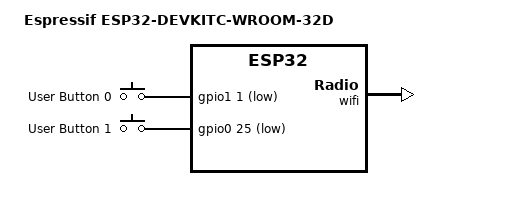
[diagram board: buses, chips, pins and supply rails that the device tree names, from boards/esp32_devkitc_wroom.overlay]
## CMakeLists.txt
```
# SPDX-License-Identifier: Apache-2.0

cmake_minimum_required(VERSION 3.20.0)

find_package(Zephyr REQUIRED HINTS $ENV{ZEPHYR_BASE})
project(mqtt_publisher)

FILE(GLOB app_sources src/*.c)
target_sources(app PRIVATE ${app_sources})
target_sources(app PRIVATE "src/zwifi/wifi.c")
```

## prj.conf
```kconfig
# Kernel options
CONFIG_MAIN_STACK_SIZE=2048
CONFIG_ENTROPY_GENERATOR=y
CONFIG_TEST_RANDOM_GENERATOR=y
CONFIG_INIT_STACKS=y

# Enable WiFi
CONFIG_WIFI=y
CONFIG_NET_L2_WIFI_MGMT=y

# Enable Networking
CONFIG_NETWORKING=y
CONFIG_NET_L2_ETHERNET=y
CONFIG_NET_IPV4=y
CONFIG_NET_TCP=y
CONFIG_NET_UDP=y

# DNS
CONFIG_DNS_RESOLVER=y
CONFIG_DNS_SERVER_IP_ADDRESSES=y
CONFIG_DNS_SERVER1="8.8.8.8"

# Enable SOCKETS
CONFIG_NET_SOCKETS=y

# Enable the MQTT Lib
CONFIG_MQTT_LIB=y

# Use DHCP for IPv4
CONFIG_NET_DHCPV4=y
CONFIG_NET_MGMT=y
CONFIG_NET_MGMT_EVENT=y

# Or assign a static IP address (useful for testing)
# Following line must be enabled, otherwise WiFi connection fails with -1.
CONFIG_NET_CONFIG_SETTINGS=y
# CONFIG_NET_CONFIG_NEED_IPV4=n
# CONFIG_NET_CONFIG_MY_IPV4_ADDR="192.168.1.30"
# CONFIG_NET_CONFIG_MY_IPV4_GW="192.168.1.1"

# Enabling BSD Sockets compatible API
#CONFIG_NET_SOCKETS=y
#CONFIG_NET_SOCKETS_POSIX_NAMES=y
CONFIG_NET_TX_STACK_SIZE=4096
CONFIG_NET_RX_STACK_SIZE=4096

# Logging
CONFIG_LOG=y
CONFIG_DEBUG=y
CONFIG_PRINTK=y
CONFIG_WIFI_LOG_LEVEL_DBG=y
CONFIG_MODEM_LOG_LEVEL_DBG=y
CONFIG_MODEM_CONTEXT_VERBOSE_DEBUG=y
```

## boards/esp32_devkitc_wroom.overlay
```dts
/*
 * Copyright (c) 2022 Espressif Systems (Shanghai) Co., Ltd.
 *
 * SPDX-License-Identifier: Apache-2.0
 */

/ {
	model = "Espressif ESP32-DEVKITC-WROOM-32D";
	compatible = "espressif,esp32";

	aliases {
		sw0 = &btn0;
		sw1 = &btn1;
	};

	buttons {
		compatible = "gpio-keys";
		btn0: btn_0 {
			gpios = <&gpio1 1 (GPIO_PULL_UP | GPIO_ACTIVE_LOW)>; //Change it to GPIO_ACTIVE_HIGH for actual state
			label = "User Button 0";
		};
		btn1: btn_1 {
			gpios = <&gpio0 25 (GPIO_PULL_UP | GPIO_ACTIVE_LOW)>; //Change it to GPIO_ACTIVE_HIGH for actual state
			label = "User Button 1";
		};
	};
};

&wifi {
	status = "okay";
};
```

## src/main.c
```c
/*
 * Copyright (c) 2017 Intel Corporation
 *
 * SPDX-License-Identifier: Apache-2.0
 */

#include <zephyr/logging/log.h>
LOG_MODULE_REGISTER(net_mqtt_publisher_sample, LOG_LEVEL_DBG);

#include <zephyr/kernel.h>
#include <zephyr/net/socket.h>
#include <zephyr/net/mqtt.h>
#include <zephyr/random/random.h>

#include <zephyr/device.h>
#include <zephyr/drivers/gpio.h>
#include <zephyr/sys/util.h>
#include <zephyr/sys/printk.h>
#include <inttypes.h>

#include <string.h>
#include <errno.h>

#include "config.h"
#include "zwifi/wifi.h"

/* Get button configuration from the devicetree sw0 alias. This is mandatory.  */
#define SW0_NODE DT_ALIAS(sw0)
#if !DT_NODE_HAS_STATUS(SW0_NODE, okay)
#error "Unsupported board: sw0 devicetree alias is not defined"
#endif
static const struct gpio_dt_spec button0 = GPIO_DT_SPEC_GET_OR(SW0_NODE, gpios, {0});

/* Buffers for MQTT client. */
#define APP_BMEM
#define APP_DMEM

static APP_BMEM uint8_t rx_buffer[APP_MQTT_BUFFER_SIZE];
static APP_BMEM uint8_t tx_buffer[APP_MQTT_BUFFER_SIZE];

/* The mqtt client struct */
static APP_BMEM struct mqtt_client client_ctx;

/* MQTT Broker details. */
static APP_BMEM struct sockaddr_storage broker;

static APP_BMEM struct zsock_pollfd fds[1];
static APP_BMEM int nfds;

static APP_BMEM bool connected;

static void prepare_fds(struct mqtt_client *client)
{
	if (client->transport.type == MQTT_TRANSPORT_NON_SECURE) {
		fds[0].fd = client->transport.tcp.sock;
	}
#if defined(CONFIG_MQTT_LIB_TLS)
	else if (client->transport.type == MQTT_TRANSPORT_SECURE) {
		fds[0].fd = client->transport.tls.sock;
	}
#endif

	fds[0].events = ZSOCK_POLLIN;
	nfds = 1;
}

static void clear_fds(void)
{
	nfds = 0;
}

static int wait(int timeout)
{
	int ret = 0;

	if (nfds > 0) {
		ret = zsock_poll(fds, nfds, timeout);
		if (ret < 0) {
			LOG_ERR("poll error: %d", errno);
		}
	}

	return ret;
}

void mqtt_evt_handler(struct mqtt_client *const client,
		      const struct mqtt_evt *evt)
{
	int err;

	switch (evt->type) {
	case MQTT_EVT_CONNACK:
		if (evt->result != 0) {
			LOG_ERR("MQTT connect failed %d", evt->result);
			break;
		}

		connected = true;
		LOG_INF("MQTT client connected!");

		break;

	case MQTT_EVT_DISCONNECT:
		LOG_INF("MQTT client disconnected %d", evt->result);

		connected = false;
		clear_fds();

		break;

	case MQTT_EVT_PUBACK:
		if (evt->result != 0) {
			LOG_ERR("MQTT PUBACK error %d", evt->result);
			break;
		}

		LOG_INF("PUBACK packet id: %u", evt->param.puback.message_id);

		break;

	case MQTT_EVT_PUBREC:
		if (evt->result != 0) {
			LOG_ERR("MQTT PUBREC error %d", evt->result);
			break;
		}

		LOG_INF("PUBREC packet id: %u", evt->param.pubrec.message_id);

		const struct mqtt_pubrel_param rel_param = {
			.message_id = evt->param.pubrec.message_id
		};

		err = mqtt_publish_qos2_release(client, &rel_param);
		if (err != 0) {
			LOG_ERR("Failed to send MQTT PUBREL: %d", err);
		}

		break;

	case MQTT_EVT_PUBCOMP:
		if (evt->result != 0) {
			LOG_ERR("MQTT PUBCOMP error %d", evt->result);
			break;
		}

		LOG_INF("PUBCOMP packet id: %u",
			evt->param.pubcomp.message_id);

		break;

	case MQTT_EVT_PINGRESP:
		LOG_INF("PINGRESP packet");
		break;

	default:
		break;
	}
}

static char *get_mqtt_payload(enum mqtt_qos qos)
{
#if APP_BLUEMIX_TOPIC
	static APP_BMEM char payload[30];

	snprintk(payload, sizeof(payload), "{d:{temperature:%d}}",
		 (uint8_t)sys_rand32_get());
#else
	static APP_DMEM char payload[] = "Button State: ";
	int val = gpio_pin_get_dt(&button0);

	payload[strlen(payload) - 1] = '0' + val;
#endif

	return payload;
}

static char *get_mqtt_topic(void)
{
#if APP_BLUEMIX_TOPIC
	return "iot-2/type/"BLUEMIX_DEVTYPE"/id/"BLUEMIX_DEVID
	       "/evt/"BLUEMIX_EVENT"/fmt/"BLUEMIX_FORMAT;
#else
	return "sensors";
#endif
}

static int publish(struct mqtt_client *client, enum mqtt_qos qos)
{
	struct mqtt_publish_param param;

	param.message.topic.qos = qos;
	param.message.topic.topic.utf8 = (uint8_t *)get_mqtt_topic();
	param.message.topic.topic.size =
			strlen(param.message.topic.topic.utf8);
	param.message.payload.data = get_mqtt_payload(qos);
	param.message.payload.len =
			strlen(param.message.payload.data);
	param.message_id = sys_rand32_get();
	param.dup_flag = 0U;
	param.retain_flag = 0U;

	return mqtt_publish(client, &param);
}

#define RC_STR(rc) ((rc) == 0 ? "OK" : "ERROR")

#define PRINT_RESULT(func, rc) \
	LOG_INF("%s: %d <%s>", (func), rc, RC_STR(rc))

static void broker_init(void)
{
	struct sockaddr_in *broker4 = (struct sockaddr_in *)&broker;

	broker4->sin_family = AF_INET;
	broker4->sin_port = htons(SERVER_PORT);
	zsock_inet_pton(AF_INET, SERVER_ADDR, &broker4->sin_addr);
}

static void client_init(struct mqtt_client *client)
{
	mqtt_client_init(client);

	broker_init();

	/* MQTT client configuration */
	client->broker = &broker;
	client->evt_cb = mqtt_evt_handler;
	client->client_id.utf8 = (uint8_t *)MQTT_CLIENTID;
	client->client_id.size = strlen(MQTT_CLIENTID);
	client->password = NULL;
	client->user_name = NULL;
	client->protocol_version = MQTT_VERSION_3_1_1;

	/* MQTT buffers configuration */
	client->rx_buf = rx_buffer;
	client->rx_buf_size = sizeof(rx_buffer);
	client->tx_buf = tx_buffer;
	client->tx_buf_size = sizeof(tx_buffer);
}

/* In this routine we block until the connected variable is 1 */
static int try_to_connect(struct mqtt_client *client)
{
	int rc, i = 0;

	while (i++ < APP_CONNECT_TRIES && !connected) {

		client_init(client);

		rc = mqtt_connect(client);
		if (rc != 0) {
			PRINT_RESULT("mqtt_connect", rc);
			k_sleep(K_MSEC(APP_SLEEP_MSECS));
			continue;
		}

		prepare_fds(client);

		if (wait(APP_CONNECT_TIMEOUT_MS)) {
			mqtt_input(client);
		}

		if (!connected) {
			mqtt_abort(client);
		}
	}

	if (connected) {
		return 0;
	}

	return -EINVAL;
}

static int process_mqtt_and_sleep(struct mqtt_client *client, int timeout)
{
	int64_t remaining = timeout;
	int64_t start_time = k_uptime_get();
	int rc;

	while (remaining > 0 && connected) {
		if (wait(remaining)) {
			rc = mqtt_input(client);
			if (rc != 0) {
				PRINT_RESULT("mqtt_input", rc);
				return rc;
			}
		}

		rc = mqtt_live(client);
		if (rc != 0 && rc != -EAGAIN) {
			PRINT_RESULT("mqtt_live", rc);
			return rc;
		} else if (rc == 0) {
			rc = mqtt_input(client);
			if (rc != 0) {
				PRINT_RESULT("mqtt_input", rc);
				return rc;
			}
		}

		remaining = timeout + start_time - k_uptime_get();
	}

	return 0;
}

#define SUCCESS_OR_EXIT(rc) { if (rc != 0) { return 1; } }
#define SUCCESS_OR_BREAK(rc) { if (rc != 0) { break; } }

static int publisher(void)
{
	int i, rc, r = 0;

	LOG_INF("attempting to connect: ");
	rc = try_to_connect(&client_ctx);
	PRINT_RESULT("try_to_connect", rc);
	SUCCESS_OR_EXIT(rc);

	i = 0;
	while (i++ < CONFIG_NET_SAMPLE_APP_MAX_ITERATIONS && connected) {
		r = -1;

		// rc = mqtt_ping(&client_ctx);
		// PRINT_RESULT("mqtt_ping", rc);
		// SUCCESS_OR_BREAK(rc);

		// rc = process_mqtt_and_sleep(&client_ctx, APP_SLEEP_MSECS);
		// SUCCESS_OR_BREAK(rc);

		rc = publish(&client_ctx, MQTT_QOS_0_AT_MOST_ONCE);
		PRINT_RESULT("mqtt_publish", rc);
		SUCCESS_OR_BREAK(rc);

		rc = process_mqtt_and_sleep(&client_ctx, APP_SLEEP_MSECS);
		SUCCESS_OR_BREAK(rc);

		r = 0;
	}

	rc = mqtt_disconnect(&client_ctx);
	PRINT_RESULT("mqtt_disconnect", rc);

	LOG_INF("Bye!");

	return r;
}

static int start_app(void)
{
	int r = 0, i = 0;

	while (!CONFIG_NET_SAMPLE_APP_MAX_CONNECTIONS ||
	       i++ < CONFIG_NET_SAMPLE_APP_MAX_CONNECTIONS) {
		r = publisher();

		if (!CONFIG_NET_SAMPLE_APP_MAX_CONNECTIONS) {
			k_sleep(K_MSEC(5000));
		}
	}

	return r;
}

uint8_t init_gpio(){
	uint8_t ret;

	if (!gpio_is_ready_dt(&button0)) {
		printk("Error: button device %s is not ready\n", button0.port->name);
		return 0;
	}

	ret = gpio_pin_configure_dt(&button0, GPIO_INPUT);
	if (ret != 0) {
		printk("Error %d: failed to configure %s pin %d\n", ret, button0.port->name,
				button0.pin);
		return 0;
	}

	printk("Set up button at %s pin %d\n", button0.port->name, button0.pin);

	return ret;
}

int main(void)
{
	init_gpio();
	init_wifi();

	// while (1){
	// 	int val = gpio_pin_get_dt(&button0);

	// 	printk("button: %d\n", val);
	// 	k_msleep(1000);
	// }

	exit(start_app());
	return 0;
}
```

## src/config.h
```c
/*
 * Copyright (c) 2017 Intel Corporation
 *
 * SPDX-License-Identifier: Apache-2.0
 */

#ifndef __CONFIG_H__
#define __CONFIG_H__

#ifdef CONFIG_NET_CONFIG_SETTINGS
// #define ZEPHYR_ADDR		"192.168.1.29"
#define SERVER_ADDR		"192.168.1.28"
#define SERVER_PORT		1883
#endif

#define APP_CONNECT_TIMEOUT_MS	5000
#define APP_SLEEP_MSECS		500

#define APP_CONNECT_TRIES	10

#define APP_MQTT_BUFFER_SIZE	256

#define MQTT_CLIENTID		"zephyr_publisher"

/* Set the following to 1 to enable the Bluemix topic format */
#define APP_BLUEMIX_TOPIC	0

/* These are the parameters for the Bluemix topic format */
#if APP_BLUEMIX_TOPIC
#define BLUEMIX_DEVTYPE		"sensor"
#define BLUEMIX_DEVID		"carbon"
#define BLUEMIX_EVENT		"status"
#define BLUEMIX_FORMAT		"json"
#endif

#endif
```

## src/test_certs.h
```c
/*
 * Copyright (c) 2016 Intel Corporation
 *
 * SPDX-License-Identifier: Apache-2.0
 */

#ifndef __TEST_CERTS_H__
#define __TEST_CERTS_H__

#if defined(CONFIG_NET_SOCKETS_OFFLOAD)
/* By default only certificates in DER format are supported. If you want to use
 * certificate in PEM format, you can enable support for it in Kconfig.
 */

#if defined(CONFIG_TLS_CREDENTIAL_FILENAMES)
static const unsigned char ca_certificate[] = "ca_cert.der";
#else
static const unsigned char ca_certificate[] = {
#include "ca_cert.der.inc"
};
#endif

#else
#include <mbedtls/ssl_ciphersuites.h>

#if defined(MBEDTLS_X509_CRT_PARSE_C)
/* This byte array can be generated by
 * "cat ca.crt | sed -e '1d;$d' | base64 -d |xxd -i"
 */
static const unsigned char ca_certificate[] = {
	0x30, 0x82, 0x02, 0xfb, 0x30, 0x82, 0x01, 0xe3,
	0xa0, 0x03, 0x02, 0x01, 0x02, 0x02, 0x09, 0x00,
	0xee, 0x10, 0x1f, 0xc1, 0xf2, 0x30, 0xe9, 0x11,
	0x30, 0x0d, 0x06, 0x09, 0x2a, 0x86, 0x48, 0x86,
	0xf7, 0x0d, 0x01, 0x01, 0x0b, 0x05, 0x00, 0x30,
	0x14, 0x31, 0x12, 0x30, 0x10, 0x06, 0x03, 0x55,
	0x04, 0x03, 0x0c, 0x09, 0x6c, 0x6f, 0x63, 0x61,
	0x6c, 0x68, 0x6f, 0x73, 0x74, 0x30, 0x1e, 0x17,
	0x0d, 0x31, 0x37, 0x30, 0x36, 0x32, 0x36, 0x31,
	0x30, 0x35, 0x36, 0x31, 0x30, 0x5a, 0x17, 0x0d,
	0x34, 0x34, 0x31, 0x31, 0x31, 0x31, 0x31, 0x30,
	0x35, 0x36, 0x31, 0x30, 0x5a, 0x30, 0x14, 0x31,
	0x12, 0x30, 0x10, 0x06, 0x03, 0x55, 0x04, 0x03,
	0x0c, 0x09, 0x6c, 0x6f, 0x63, 0x61, 0x6c, 0x68,
	0x6f, 0x73, 0x74, 0x30, 0x82, 0x01, 0x22, 0x30,
	0x0d, 0x06, 0x09, 0x2a, 0x86, 0x48, 0x86, 0xf7,
	0x0d, 0x01, 0x01, 0x01, 0x05, 0x00, 0x03, 0x82,
	0x01, 0x0f, 0x00, 0x30, 0x82, 0x01, 0x0a, 0x02,
	0x82, 0x01, 0x01, 0x00, 0xc6, 0x00, 0x7b, 0x0d,
	0xd1, 0x17, 0x43, 0x6b, 0xa9, 0xa7, 0x79, 0x9c,
	0x0f, 0x8d, 0x77, 0x91, 0xd2, 0xf7, 0x47, 0x35,
	0xb3, 0x17, 0xe2, 0xdd, 0xed, 0x6d, 0x01, 0xf9,
	0xb1, 0x92, 0xc9, 0x48, 0x80, 0xe0, 0x1f, 0xcf,
	0xb7, 0xa4, 0x5f, 0xf0, 0x36, 0xea, 0xbf, 0xe1,
	0x33, 0xf8, 0xa9, 0xc5, 0xe6, 0xd4, 0x19, 0x8b,
	0x82, 0x25, 0xd9, 0x19, 0x74, 0x70, 0x79, 0xec,
	0xc6, 0x68, 0xc9, 0xef, 0xce, 0x1a, 0xa9, 0xf0,
	0xb7, 0x01, 0x35, 0x91, 0xff, 0xd3, 0x75, 0x6e,
	0x02, 0xba, 0x06, 0x9a, 0x2a, 0xac, 0xcf, 0x22,
	0xbf, 0x2b, 0x1f, 0xc1, 0x72, 0x38, 0x22, 0x35,
	0xea, 0xda, 0x6f, 0xdd, 0x67, 0xa2, 0x2b, 0x19,
	0x38, 0x19, 0x0e, 0x44, 0xd1, 0x71, 0x38, 0xb4,
	0x6d, 0x26, 0x85, 0xd6, 0xc6, 0xbe, 0xc1, 0x6f,
	0x3c, 0xee, 0xaf, 0x94, 0x3c, 0x05, 0x56, 0x4e,
	0xad, 0x53, 0x81, 0x8b, 0xd4, 0x23, 0x31, 0x69,
	0x72, 0x27, 0x93, 0xb4, 0x3a, 0xac, 0x23, 0xe8,
	0x10, 0xae, 0xf5, 0x9f, 0x0b, 0xa6, 0x6e, 0xd3,
	0x73, 0xca, 0x18, 0x11, 0xca, 0xbe, 0x71, 0x00,
	0x56, 0x29, 0x34, 0x54, 0xcc, 0xda, 0x29, 0x5b,
	0x26, 0x29, 0x99, 0x4d, 0x5f, 0xa1, 0xa6, 0xb9,
	0xcb, 0x2b, 0xb2, 0x0f, 0x10, 0x00, 0x04, 0xa9,
	0x11, 0x2c, 0x48, 0xb1, 0x99, 0xa5, 0xca, 0x7c,
	0x67, 0xa5, 0xbe, 0x14, 0x20, 0x12, 0xb7, 0x3b,
	0x7a, 0x4f, 0xdc, 0xc7, 0xd5, 0x2d, 0x04, 0x66,
	0xbb, 0xf5, 0x0c, 0xcd, 0xf1, 0x32, 0x39, 0xd7,
	0x51, 0x9b, 0xba, 0xdb, 0xf1, 0xa7, 0xfe, 0x2d,
	0x9a, 0xe6, 0x9c, 0x6b, 0x54, 0xda, 0xf1, 0xdd,
	0x48, 0xf9, 0xd7, 0xf0, 0x35, 0x7c, 0x8e, 0x24,
	0x7e, 0x44, 0x2f, 0xf3, 0xbf, 0x39, 0x0e, 0x96,
	0xab, 0xe1, 0x45, 0x03, 0x8b, 0x54, 0xdc, 0xe1,
	0xb6, 0x11, 0x81, 0x21, 0x02, 0x03, 0x01, 0x00,
	0x01, 0xa3, 0x50, 0x30, 0x4e, 0x30, 0x1d, 0x06,
	0x03, 0x55, 0x1d, 0x0e, 0x04, 0x16, 0x04, 0x14,
	0xa4, 0xef, 0x6d, 0xdc, 0x9b, 0x23, 0xc5, 0x3a,
	0xdd, 0x34, 0xd9, 0x01, 0x1c, 0x68, 0x03, 0x53,
	0xae, 0x92, 0xc2, 0xc9, 0x30, 0x1f, 0x06, 0x03,
	0x55, 0x1d, 0x23, 0x04, 0x18, 0x30, 0x16, 0x80,
	0x14, 0xa4, 0xef, 0x6d, 0xdc, 0x9b, 0x23, 0xc5,
	0x3a, 0xdd, 0x34, 0xd9, 0x01, 0x1c, 0x68, 0x03,
	0x53, 0xae, 0x92, 0xc2, 0xc9, 0x30, 0x0c, 0x06,
	0x03, 0x55, 0x1d, 0x13, 0x04, 0x05, 0x30, 0x03,
	0x01, 0x01, 0xff, 0x30, 0x0d, 0x06, 0x09, 0x2a,
	0x86, 0x48, 0x86, 0xf7, 0x0d, 0x01, 0x01, 0x0b,
	0x05, 0x00, 0x03, 0x82, 0x01, 0x01, 0x00, 0x67,
	0x65, 0xbf, 0x93, 0x89, 0xde, 0x4f, 0x71, 0xff,
	0x1c, 0x93, 0x68, 0xa0, 0x64, 0x09, 0x5e, 0x95,
	0x94, 0xf5, 0xd5, 0xf4, 0x6b, 0x20, 0x32, 0xd8,
	0x04, 0x80, 0xac, 0xf8, 0x52, 0x36, 0x7a, 0x38,
	0x83, 0xae, 0xab, 0x29, 0x22, 0x42, 0x71, 0x7e,
	0xea, 0xe5, 0x4f, 0x71, 0xac, 0x44, 0x3f, 0x9e,
	0x5e, 0x49, 0x22, 0x05, 0xee, 0xa6, 0x7b, 0xab,
	0x56, 0x2e, 0xb3, 0x9a, 0x35, 0x1a, 0x88, 0xc3,
	0x54, 0x9b, 0xfd, 0xac, 0x65, 0x54, 0xaf, 0x21,
	0xa7, 0xe0, 0xdd, 0x62, 0x29, 0x8c, 0xae, 0x26,
	0x0b, 0x84, 0x1f, 0x69, 0x78, 0x84, 0xc6, 0x7e,
	0xcf, 0xc8, 0xf5, 0x92, 0x8c, 0x05, 0xa8, 0x13,
	0x38, 0xcd, 0x0b, 0x98, 0x53, 0xfb, 0xdd, 0x8d,
	0x51, 0x90, 0xa8, 0x51, 0xfa, 0x52, 0xbe, 0x28,
	0xd4, 0x71, 0x50, 0x73, 0x1f, 0xb0, 0xb6, 0x0e,
	0x45, 0xb1, 0x47, 0x41, 0x06, 0xd9, 0x1d, 0x7a,
	0x34, 0xe7, 0x80, 0x2e, 0x0c, 0x02, 0x50, 0x97,
	0xde, 0xa8, 0x7a, 0x84, 0x2c, 0x1d, 0xf4, 0x51,
	0x56, 0xa5, 0x52, 0xb5, 0x04, 0x2e, 0xcb, 0xdd,
	0x8b, 0x2e, 0x16, 0xc6, 0xde, 0xc8, 0xe9, 0x8d,
	0xee, 0x5e, 0xb6, 0xa0, 0xe0, 0x2b, 0x85, 0x2a,
	0x89, 0x7b, 0xba, 0x68, 0x80, 0x2b, 0xfb, 0x6e,
	0x2e, 0x80, 0xe7, 0x7a, 0x97, 0x09, 0xb5, 0x2f,
	0x20, 0x8e, 0xed, 0xbc, 0x98, 0x6f, 0x95, 0xd5,
	0x5b, 0x3d, 0x26, 0x19, 0x26, 0x14, 0x39, 0x82,
	0xa8, 0xa8, 0x42, 0x46, 0xab, 0x59, 0x93, 0x47,
	0x83, 0xf7, 0x79, 0xbf, 0x73, 0xb5, 0x5d, 0x5d,
	0x78, 0xfe, 0x62, 0xac, 0xed, 0xb7, 0x1e, 0x4a,
	0xad, 0xc3, 0x99, 0x39, 0x7d, 0x3e, 0x30, 0x21,
	0x26, 0x1d, 0x66, 0xdb, 0x0d, 0xf3, 0xba, 0x87,
	0x46, 0xf0, 0x04, 0xfc, 0xc3, 0xbe, 0x84, 0x85,
	0x3c, 0x01, 0xef, 0xe0, 0x68, 0x65, 0xee,
};
#endif /* MBEDTLS_X509_CRT_PARSE_C */

#if defined(MBEDTLS_KEY_EXCHANGE_SOME_PSK_ENABLED)
/* Avoid leading zero in psk because there's a potential issue of mosquitto
 * that leading zero of psk will be skipped and it leads to TLS handshake
 * failure
 */
const unsigned char client_psk[] = {
	0x01, 0x01, 0x02, 0x03, 0x04, 0x05, 0x06, 0x07,
	0x08, 0x09, 0x0a, 0x0b, 0x0c, 0x0d, 0x0e, 0x0f
};

const char client_psk_id[] = "Client_identity";
#endif

#endif /* CONFIG_NET_SOCKETS_OFFLOAD */

#endif
```
